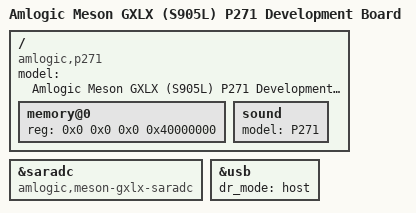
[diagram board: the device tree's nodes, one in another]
// SPDX-License-Identifier: (GPL-2.0+ OR MIT)
/*
 * Copyright (c) 2024 Christian Hewitt <christianshewitt@gmail.com>
 */

/dts-v1/;

#include "meson-gxl-s905x.dtsi"
#include "meson-gx-p23x-q20x.dtsi"

/ {
	compatible = "amlogic,p271", "amlogic,s905l", "amlogic,meson-gxl";
	model = "Amlogic Meson GXLX (S905L) P271 Development Board";

	memory@0 {
		device_type = "memory";
		reg = <0x0 0x0 0x0 0x40000000>;
	};

	sound {
		model = "P271";
	};
};

&saradc {
	compatible = "amlogic,meson-gxlx-saradc", "amlogic,meson-saradc";
};

&usb {
	dr_mode = "host";
};
